# STM32U3C5 register map
File version: 1.0
CPU: CM33 r0p1, little endian, MPU, FPU, 4 interrupt priority bits
Registers are 32-bit, read-write, reset 0x0 unless marked. A register's access mark holds for its fields unless they carry their own. Offsets are from the block's base; [hi:lo] are bit positions.

## GTZC1_TZSC — GTZC1_TZSC address block description
Base 0x40032400
Same registers: SEC_GTZC1_TZSC 0x50032400
0x00 GTZC1_TZSC_CR — GTZC1 TZSC control register
  [0] LCK — Lock GTZC1_TZSC_SECCFGRx and GTZC1_TZSC_PRIVCFGRx configuration untilnext reset
    0=Configuration of all GTZC1_TZSC_SECCFGRx and GTZC1_TZSC_PRIVCFGRx registers not locked; 1=Configuration of all GTZC1_TZSC_SECCFGRx and GTZC1_TZSC_PRIVCFGRx registers locked
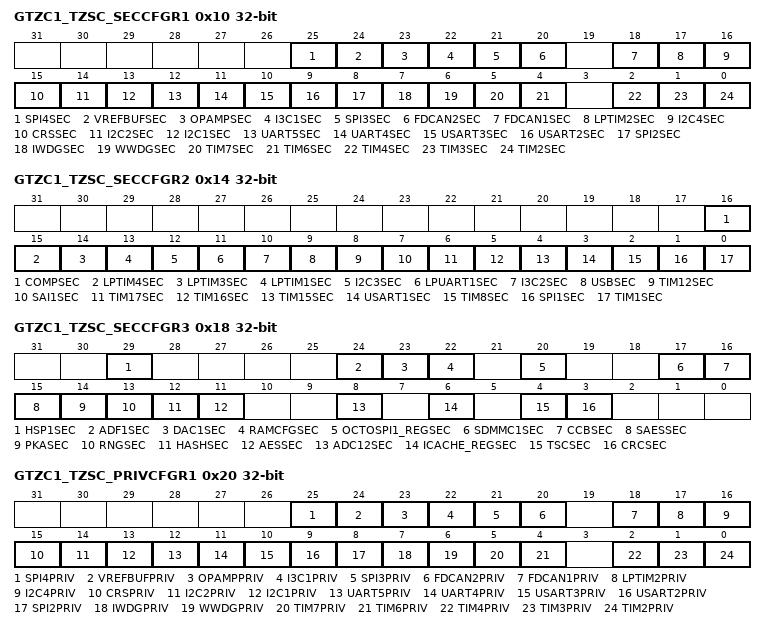
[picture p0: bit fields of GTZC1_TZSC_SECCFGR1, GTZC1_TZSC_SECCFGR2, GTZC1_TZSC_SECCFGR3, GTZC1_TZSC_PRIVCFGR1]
0x10 GTZC1_TZSC_SECCFGR1 — GTZC1 TZSC secure configuration register 1
  [all] fields
    0=Nonsecure; 1=Secure
  [25] SPI4SEC — Secure access mode for VREFBUF
  [24] VREFBUFSEC — Secure access mode for VREFBUF
  [23] OPAMPSEC — Secure access mode for OPAMP
  [22] I3C1SEC — Secure access mode for I3C1
  [21] SPI3SEC — Secure access mode for SPI3
  [20] FDCAN2SEC — Secure access mode for FDCAN2
  [18] FDCAN1SEC — Secure access mode for FDCAN1
  [17] LPTIM2SEC — Secure access mode for LPTIM2
  [16] I2C4SEC — Secure access mode for I2C4
  [15] CRSSEC — Secure access mode for CRS
  [14] I2C2SEC — Secure access mode for I2C2
  [13] I2C1SEC — Secure access mode for I2C1
  [12] UART5SEC — Secure access mode for UART5
  [11] UART4SEC — Secure access mode for UART4
  [10] USART3SEC — Secure access mode for USART3
  [9] USART2SEC — Secure access mode for USART2
  [8] SPI2SEC — Secure access mode for SPI2
  [7] IWDGSEC — Secure access mode for IWDG
  [6] WWDGSEC — Secure access mode for WWDG
  [5] TIM7SEC — Secure access mode for TIM7
  [4] TIM6SEC — Secure access mode for TIM6
  [2] TIM4SEC — Secure access mode for TIM4
  [1] TIM3SEC — Secure access mode for TIM3
  [0] TIM2SEC — Secure access mode for TIM2
0x14 GTZC1_TZSC_SECCFGR2 — GTZC1 TZSC secure configuration register 2
  [all] fields
    0=Nonsecure; 1=Secure
  [16] COMPSEC — Secure access mode for COMP
  [15] LPTIM4SEC — Secure access mode for LPTIM4
  [14] LPTIM3SEC — Secure access mode for LPTIM3
  [13] LPTIM1SEC — Secure access mode for LPTIM1
  [12] I2C3SEC — Secure access mode for I2C3
  [11] LPUART1SEC — Secure access mode for LPUART1
  [10] I3C2SEC — Secure access mode for I3C2
  [9] USBSEC — Secure access mode for USB
  [8] TIM12SEC — Secure access mode for TIM12
  [7] SAI1SEC — Secure access mode for SAI1
  [6] TIM17SEC — Secure access mode for TIM17
  [5] TIM16SEC — Secure access mode for TIM16
  [4] TIM15SEC — Secure access mode for TIM15
  [3] USART1SEC — Secure access mode for USART1
  [2] TIM8SEC — Secure access mode for TIM8
  [1] SPI1SEC — Secure access mode for SPI1
  [0] TIM1SEC — Secure access mode for TIM1
0x18 GTZC1_TZSC_SECCFGR3 — GTZC1 TZSC secure configuration register 3
  [all] fields
    0=Nonsecure; 1=Secure
  [29] HSP1SEC — Secure access mode for HSP1
  [24] ADF1SEC — Secure access mode for ADF1
  [23] DAC1SEC — Secure access mode for DAC1
  [22] RAMCFGSEC — Secure access mode for RAMCFG
  [20] OCTOSPI1_REGSEC — Secure access mode for OCTOSPI1 registers
  [17] SDMMC1SEC — Secure access mode for SDMMC1
  [16] CCBSEC — Secure access mode for CCB
  [15] SAESSEC — Secure access mode for SAES
  [14] PKASEC — Secure access mode for PKA
  [13] RNGSEC — Secure access mode for RNG
  [12] HASHSEC — Secure access mode for HASH
  [11] AESSEC — Secure access mode for AES
  [8] ADC12SEC — Secure access mode for ADC1 and ADC2
  [6] ICACHE_REGSEC — Secure access mode for ICACHE registers
  [4] TSCSEC — Secure access mode for TSC
  [3] CRCSEC — Secure access mode for CRC
0x20 GTZC1_TZSC_PRIVCFGR1 — GTZC1 TZSC privilege configuration register 1
  [all] fields
    0=Unprivileged; 1=Privileged
  [25] SPI4PRIV — Privileged access mode for SPI4
  [24] VREFBUFPRIV — Privileged access mode for VREFBUF
  [23] OPAMPPRIV — Privileged access mode for OPAMP
  [22] I3C1PRIV — Privileged access mode for I3C1
  [21] SPI3PRIV — Privileged access mode for SPI3
  [20] FDCAN2PRIV — Privileged access mode for FDCAN2
  [18] FDCAN1PRIV — Privileged access mode for FDCAN1
  [17] LPTIM2PRIV — Privileged access mode for LPTIM2
  [16] I2C4PRIV — Privileged access mode for I2C4
  [15] CRSPRIV — Privileged access mode for CRS
  [14] I2C2PRIV — Privileged access mode for I2C2
  [13] I2C1PRIV — Privileged access mode for I2C1
  [12] UART5PRIV — Privileged access mode for UART5
  [11] UART4PRIV — Privileged access mode for UART4
  [10] USART3PRIV — Privileged access mode for USART3
  [9] USART2PRIV — Privileged access mode for USART2
  [8] SPI2PRIV — Privileged access mode for SPI2
  [7] IWDGPRIV — Privileged access mode for IWDG
  [6] WWDGPRIV — Privileged access mode for WWDG
  [5] TIM7PRIV — Privileged access mode for TIM7
  [4] TIM6PRIV — Privileged access mode for TIM6
  [2] TIM4PRIV — Privileged access mode for TIM4
  [1] TIM3PRIV — Privileged access mode for TIM3
  [0] TIM2PRIV — Privileged access mode for TIM2
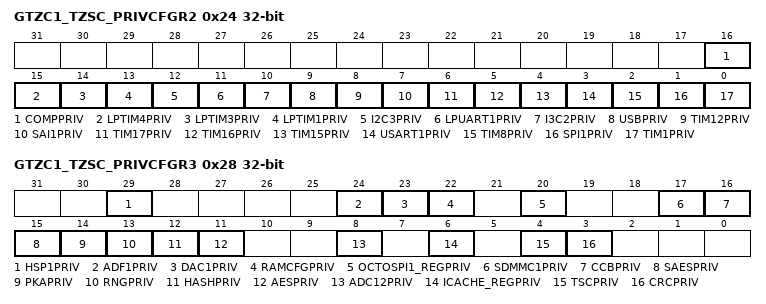
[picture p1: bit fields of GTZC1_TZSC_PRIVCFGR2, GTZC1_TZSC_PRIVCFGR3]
0x24 GTZC1_TZSC_PRIVCFGR2 — GTZC1 TZSC privilege configuration register 2
  [all] fields
    0=Unprivileged; 1=Privileged
  [16] COMPPRIV — Privileged access mode for COMP
  [15] LPTIM4PRIV — Privileged access mode for LPTIM4
  [14] LPTIM3PRIV — Privileged access mode for LPTIM3
  [13] LPTIM1PRIV — Privileged access mode for LPTIM1
  [12] I2C3PRIV — Privileged access mode for I2C3
  [11] LPUART1PRIV — Privileged access mode for LPUART1
  [10] I3C2PRIV — Privileged access mode for I3C2
  [9] USBPRIV — Privileged access mode for USB
  [8] TIM12PRIV — Privileged access mode for TIM12
  [7] SAI1PRIV — Privileged access mode for SAI1
  [6] TIM17PRIV — Privileged access mode for TIM17
  [5] TIM16PRIV — Privileged access mode for TIM16
  [4] TIM15PRIV — Privileged access mode for TIM15
  [3] USART1PRIV — Privileged access mode for USART1
  [2] TIM8PRIV — Privileged access mode for TIM8
  [1] SPI1PRIV — Privileged access mode for SPI1
  [0] TIM1PRIV — Privileged access mode for TIM1
0x28 GTZC1_TZSC_PRIVCFGR3 — GTZC1 TZSC privilege configuration register 3
  [all] fields
    0=Unprivileged; 1=Privileged
  [29] HSP1PRIV — Privileged access mode for HSP1
  [24] ADF1PRIV — Privileged access mode for ADF1
  [23] DAC1PRIV — Privileged access mode for DAC1
  [22] RAMCFGPRIV — Privileged access mode for RAMCFG
  [20] OCTOSPI1_REGPRIV — Privileged access mode for OCTOSPI1 registers
  [17] SDMMC1PRIV — Privileged access mode for SDMMC1
  [16] CCBPRIV — Privileged access mode for CCB
  [15] SAESPRIV — Privileged access mode for SAES
  [14] PKAPRIV — Privileged access mode for PKA
  [13] RNGPRIV — Privileged access mode for RNG
  [12] HASHPRIV — Privileged access mode for HASH
  [11] AESPRIV — Privileged access mode for AES
  [8] ADC12PRIV — Privileged access mode for ADC1 and ADC2
  [6] ICACHE_REGPRIV — Privileged access mode for ICACHE registers
  [4] TSCPRIV — Privileged access mode for TSC
  [3] CRCPRIV — Privileged access mode for CRC

## Notices in the file
Copyright (c) 2025 STMicroelectronics.
SPDx-License-Identifier: Apache-2.0
Licensed under the Apache License, Version 2.0 (the "License");
you may not use this file except in compliance with the License.
You may obtain a copy of the License at
http://www.apache.org/licenses/LICENSE-2.0
Unless required by applicable law or agreed to in writing, software
distributed under the License is distributed on an "AS IS" BASIS,
WITHOUT WARRANTIES OR CONDITIONS OF ANY KIND, either express or implied.
See the License for the specific language governing permissions and
limitations under the License.
